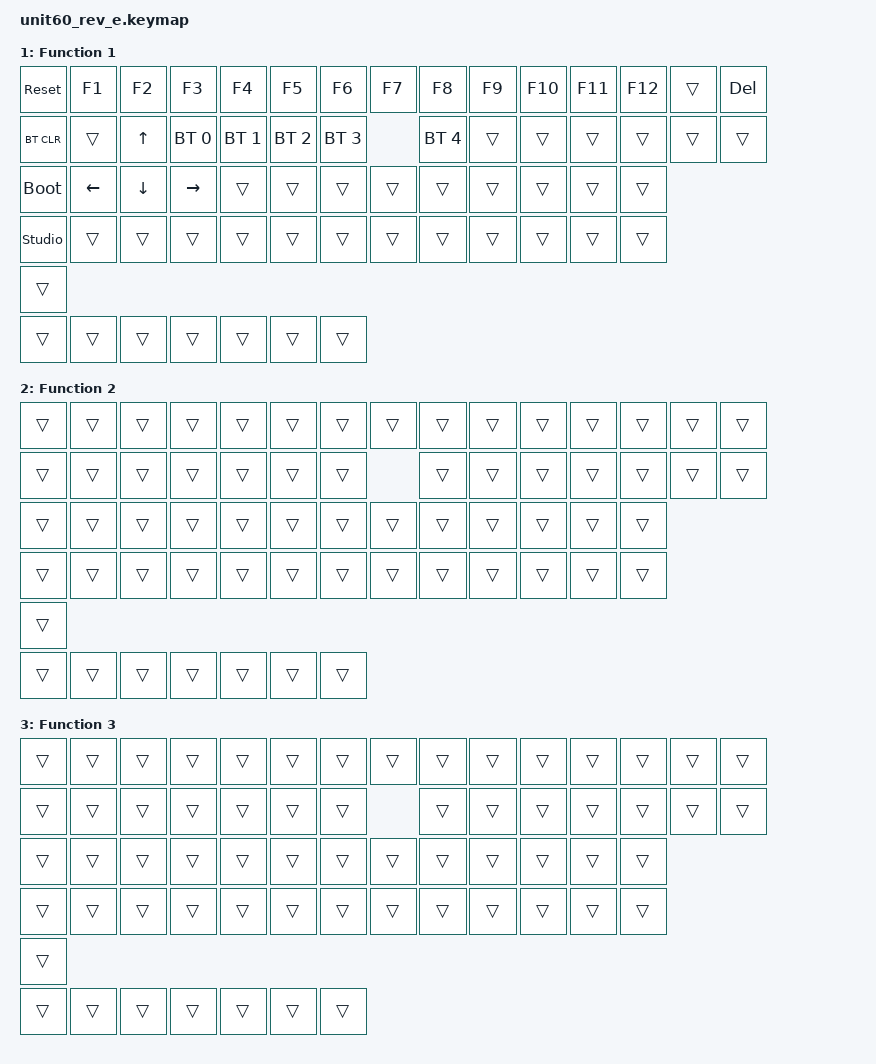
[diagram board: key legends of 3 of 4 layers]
#include <behaviors.dtsi>
#include <dt-bindings/zmk/bt.h>
#include <dt-bindings/zmk/keys.h>
#include <dt-bindings/zmk/rgb.h>

/ {
    combos {
        compatible = "zmk,combos";
        /* 示例组合键：Q+W=Esc，可在 ZMK Studio 中删除或修改 */
        combo_esc_demo {
            timeout-ms = <50>;
            key-positions = <16 17>;
            bindings = <&kp ESC>;
        };
    };

    keymap {
        compatible = "zmk,keymap";
        default_layer {
            // Base layer - 65% layout (62 keys)
            display-name = "Base";
            bindings = <
            &kp ESC   &kp N1    &kp N2    &kp N3    &kp N4    &kp N5    &kp N6    &kp N7    &kp N8    &kp N9    &kp N0    &kp MINUS &kp EQUAL &kp BSPC  &kp DEL
            &kp TAB   &kp Q     &kp W     &kp E     &kp R     &kp T     &kp Y     &kp U     &kp I     &kp O     &kp P     &kp BSLH  &kp LBKT  &kp RBKT
            &kp CLCK  &kp A     &kp S     &kp D     &kp F     &kp G     &kp H     &kp J     &kp K     &kp L     &kp RET   &kp SEMI  &kp SQT
            &kp LSHFT &kp Z     &kp X     &kp C     &kp V     &kp B     &kp N     &kp M     &kp FSLH  &kp RSHFT &kp COMMA &kp DOT
            &kp UP
            &kp LCTRL &kp LALT  &kp SPACE &mo 1     &kp LEFT  &kp DOWN  &kp RIGHT
            >;
        };

        fn_layer_0 {
            display-name = "Function 1";
            bindings = <
            &sys_reset  &kp F1    &kp F2    &kp F3     &kp F4     &kp F5     &kp F6     &kp F7     &kp F8     &kp F9     &kp F10   &kp F11   &kp F12   &trans    &kp DEL
            &bt BT_CLR  &trans    &kp UP    &bt BT_SEL 0 &bt BT_SEL 1 &bt BT_SEL 2 &bt BT_SEL 3 &bt BT_SEL 4 &trans    &trans    &trans    &trans    &trans    &trans
            &bootloader &kp LEFT  &kp DOWN  &kp RIGHT  &trans     &trans     &trans     &trans     &trans     &trans     &trans    &trans    &trans
            &studio_unlock &trans &trans    &trans     &trans     &trans     &trans     &trans     &trans     &trans    &trans &trans &trans
            &trans
            &trans      &trans    &trans    &trans     &trans     &trans     &trans
            >;
        };

        fn_layer_1 {
            display-name = "Function 2";
            bindings = <
            &trans &trans &trans &trans &trans &trans &trans &trans &trans &trans &trans &trans &trans &trans &trans
            &trans &trans &trans &trans &trans &trans &trans &trans &trans &trans &trans &trans &trans &trans
            &trans &trans &trans &trans &trans &trans &trans &trans &trans &trans &trans &trans &trans
            &trans &trans &trans &trans &trans &trans &trans &trans &trans &trans &trans &trans &trans
            &trans
            &trans &trans &trans &trans &trans &trans &trans
            >;
        };

        fn_layer_2 {
            display-name = "Function 3";
            bindings = <
            &trans &trans &trans &trans &trans &trans &trans &trans &trans &trans &trans &trans &trans &trans &trans
            &trans &trans &trans &trans &trans &trans &trans &trans &trans &trans &trans &trans &trans &trans
            &trans &trans &trans &trans &trans &trans &trans &trans &trans &trans &trans &trans &trans
            &trans &trans &trans &trans &trans &trans &trans &trans &trans &trans &trans &trans &trans
            &trans
            &trans &trans &trans &trans &trans &trans &trans
            >;
        };
    };
};
